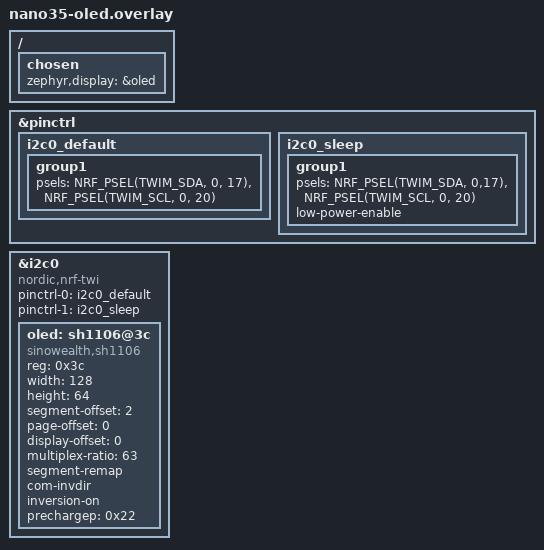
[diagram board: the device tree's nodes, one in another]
// Sofle SH1106 pins retained; logical framebuffer is 128x64.
/ { chosen { zephyr,display = &oled; }; };
&pinctrl {
    i2c0_default: i2c0_default {
        group1 {
            psels = <NRF_PSEL(TWIM_SDA, 0, 17)>,
                <NRF_PSEL(TWIM_SCL, 0, 20)>;
        };
    };

    i2c0_sleep: i2c0_sleep {
        group1 {
            psels = <NRF_PSEL(TWIM_SDA, 0,17)>,
                <NRF_PSEL(TWIM_SCL, 0, 20)>;
            low-power-enable;
        };
    };
};

&i2c0 {
	status = "okay";
	compatible = "nordic,nrf-twi";
    pinctrl-0 = <&i2c0_default>;
    pinctrl-1 = <&i2c0_sleep>;
	oled: sh1106@3c {
        compatible = "sinowealth,sh1106";
        reg = <0x3c>;
        width = <128>;
        height = <64>;
        // SH1106 has 132 RAM columns; this 128-column panel uses 2..129.
        // Offset 1 leaves one visible edge column unwritten after width=128.
        segment-offset = <2>;
        page-offset = <0>;
        display-offset = <0>;
        multiplex-ratio = <63>;
        segment-remap;
        com-invdir;
        inversion-on;
        prechargep = <0x22>;
	};
};
